AUTOSAR XML (schema 4-0-3)
package /ComponentTypes
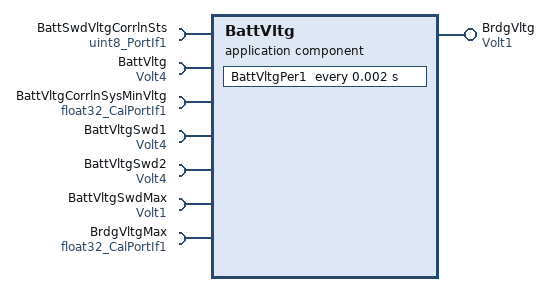
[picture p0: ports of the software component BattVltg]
  application sw component type BattVltg
    provide port BrdgVltg: nonqueued-sender-com-spec{data-element=Val, init-value=6}, provided-interface=Volt1
    7 x require port:
      BattSwdVltgCorrlnSts: nonqueued-receiver-com-spec{data-element=Val, filter=data-filter-type=ALWAYS, init-value=7}, required-interface=uint8_PortIf1
      BattVltg: nonqueued-receiver-com-spec{data-element=Val, filter=data-filter-type=ALWAYS, init-value=0}, required-interface=Volt4
      BattVltgCorrlnSysMinVltg: parameter-require-com-spec{init-value=6, parameter=Val}, required-interface=float32_CalPortIf1
      BattVltgSwd1: nonqueued-receiver-com-spec{data-element=Val, filter=data-filter-type=ALWAYS, init-value=0}, required-interface=Volt4
      BattVltgSwd2: nonqueued-receiver-com-spec{data-element=Val, filter=data-filter-type=ALWAYS, init-value=0}, required-interface=Volt4
      BattVltgSwdMax: parameter-require-com-spec{init-value=16, parameter=Val}, required-interface=Volt1
      BrdgVltgMax: parameter-require-com-spec{init-value=26.5, parameter=Val}, required-interface=float32_CalPortIf1
    behavior BattVltg_InternalBehavior: data-type-mapping=Nexteer
      timing event TMT_BattVltgPer1: start-on-event=BattVltgPer1, period=0.002
      runnable BattVltgPer1
        data-receive-point-by-arguments:
          5 x access:
            REC_BattSwdVltgCorrlnSts_Val: accessed-variable=BattSwdVltgCorrlnSts.Val
            REC_BattSwdVltgCorrlnSts_Val_1: accessed-variable=BattSwdVltgCorrlnSts.Val
            REC_BattVltg_Val: accessed-variable=BattVltg.Val
            REC_BattVltgSwd1_Val: accessed-variable=BattVltgSwd1.Val
            REC_BattVltgSwd2_Val: accessed-variable=BattVltgSwd2.Val
        data-send-points:
          access REC_BrdgVltg_Val: accessed-variable=BrdgVltg.Val
  swc implementation BattVltg_Implementation: behavior=BattVltg_InternalBehavior
    code-descriptors:
      code Default: artifact-descriptors=autosar-engineering-object={short-label=Default, category=SWSRC}
